# CEC1734_S0_2ZW register map
Vendor: Microchip Technology; Series: CEC; File version: 0
CPU: CM4 r1p0, little endian, MPU, FPU, 3 interrupt priority bits, 196 interrupts
Registers are 32-bit, read-write, reset 0x0 unless marked. A register's access mark holds for its fields unless they carry their own. Offsets are from the block's base; [hi:lo] are bit positions; {n}, {i} and the like mark numbered series.

## IMSPI — Internal Master SPI.
Base 0x40220000; register names take the prefix IMSPI_
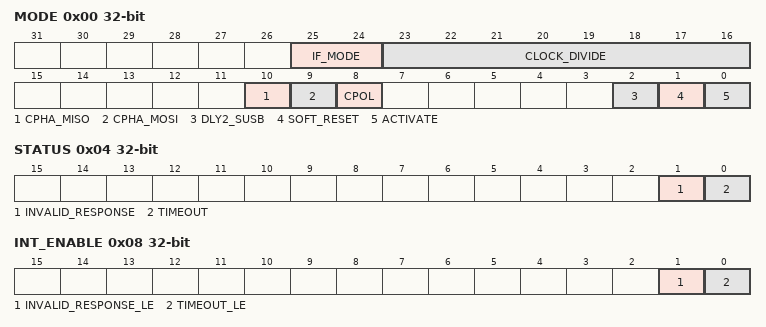
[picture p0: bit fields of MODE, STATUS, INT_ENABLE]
0x00 MODE — IMSPI Mode Register
  [25:24] IF_MODE — This field sets the interface mode for the SPI controller. 3=Reserved; 2=Quad Mode; 1=Dual Mode; 0=Single Mode.
  [23:16] CLOCK_DIVIDE — This SPI clock divide in terms of the number of system clocks. 255:1=The SPI clock period is equal to this number of system clocks. 0=The SPI clock period is equal to 256 system clocks.
  [10] CPHA_MISO — This field is the CPHA field of the underlying SPI controller which affects only the MISO Data. This field changes determines the clock edge on which data are captured, in combination with the CPOL field. For standard SPI Modes, this must be programmed with the same value as CPHA_MOSI. 1=If CPOL=0, data captured on Falling Edge; if CPOL=1, data captured on Rising Edge 0=If CPOL=0, data captured on Rising Edge; if CPOL=1, data captured on Falling Edge.
  [9] CPHA_MOSI — This field is the CPHA field of the underlying SPI controller which affects only the MOSI Data. This field changes determines the clock edge on which data are sent, in combination with the CPOL field. 1=If CPOL=0, data sent on Rising Edge; if CPOL=1, data sent on Falling Edge ; 0=If CPOL=0, data sent on Falling Edge; if CPOL=1, data sent on Rising Edge.
  [8] CPOL — This bit corresponds to the Polarity control for the underlying SPI controller. It describes the default state of the SPI Clock signal. 1=The clock starts in a high state; 0=The clock starts in a low state.
  [2] DLY2_SUSB — This bit is routed to the DLY2_SUSB# pin function.
  [1] SOFT_RESET — A write of '1b' to this bit resets the controller. This bit is self-clearing.
  [0] ACTIVATE — This bit enables the controller. 1=The controller is enabled; 0=The controller is disabled and placed in its lowest power state.
0x04 STATUS — IMSPI Status Register
  [1] INVALID_RESPONSE — The IMSPI has detected an invalid response field and therefore is aborting the transfer in failure. 1=A transfer error occurred due to an invalid response; 0=No error occurred. (R/WC)
  [0] TIMEOUT — This flags when a transfer has terminated due to timeout on the response phase. 1=A transfer error occurred due to an invalid response; 0=No error occurred. (R/WC)
0x08 INT_ENABLE — IMSPI Interrupt Enable Register
  [1] INVALID_RESPONSE_LE — Assert an EEPROM interrupt when the INVALID_RESPONSE status is asserted. 1=Enable Interrupt; 0=Disable Interrupt
  [0] TIMEOUT_LE — Assert an IMSPI interrupt when the TIMEOUT status is asserted. 1=Enable Interrupt; 0=Disable Interrupt
0x0C TIMEOUT_CONTROL — IMSPI Timeout Control Register
  [4:0] RESPONSE_TIMEOUT — This field is the maximum number of response cycles the IMSPI will wait until flagging a timeout. A setting of 0 will disable the timeout feature.

## NVIC — Nested Vectored Interrupt Controller
Base 0xE000E100; register names take the prefix NVIC_
{0x0+4i} ISER[{i}] (i=0..0) — Interrupt Set Enable Register
  [31:0] SETENA — Interrupt set enable bits
{0x80+4i} ICER[{i}] (i=0..0) — Interrupt Clear Enable Register
  [31:0] CLRENA — Interrupt clear-enable bits
{0x100+4i} ISPR[{i}] (i=0..0) — Interrupt Set Pending Register
  [31:0] SETPEND — Interrupt set-pending bits
{0x180+4i} ICPR[{i}] (i=0..0) — Interrupt Clear Pending Register
  [31:0] CLRPEND — Interrupt clear-pending bits
{0x200+4i} IABR[{i}] (i=0..0) — Interrupt Active Bit Register
  [31:0] ACTIVE — Interrupt active bits
{0x300+i} IP[{i}] (i=0..7) 8-bit — Interrupt Priority Register n
  [2:0] PRI0 — Priority of interrupt n
0xE00 STIR wo — Software Trigger Interrupt Register
  [8:0] INTID — Interrupt ID to trigger

## SysTick — System timer
Base 0xE000E010; register names take the prefix SysTick_
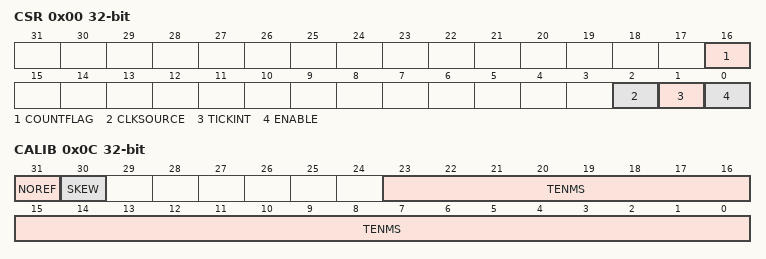
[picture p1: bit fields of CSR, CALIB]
0x00 CSR — SysTick Control and Status Register
  [16] COUNTFLAG — Timer counted to 0 since last read of register
  [2] CLKSOURCE — Clock Source 0=external, 1=processor
    0=External clock; 1=Processor clock
  [1] TICKINT — SysTick Exception Request Enable
    0=Counting down to 0 does not assert the SysTick exception request; 1=Counting down to 0 asserts the SysTick exception request
  [0] ENABLE — SysTick Counter Enable
    0=Counter disabled; 1=Counter enabled
0x04 RVR — SysTick Reload Value Register
  [23:0] RELOAD — Value to load into the SysTick Current Value Register when the counter reaches 0
0x08 CVR — SysTick Current Value Register
  [23:0] CURRENT — Current value at the time the register is accessed
0x0C CALIB ro — SysTick Calibration Value Register
  [31] NOREF — No Separate Reference Clock
    0=The reference clock is provided; 1=The reference clock is not provided
  [30] SKEW — TENMS is rounded from non-integer ratio
    0=10ms calibration value is exact; 1=10ms calibration value is inexact, because of the clock frequency
  [23:0] TENMS — Reload value to use for 10ms timing
